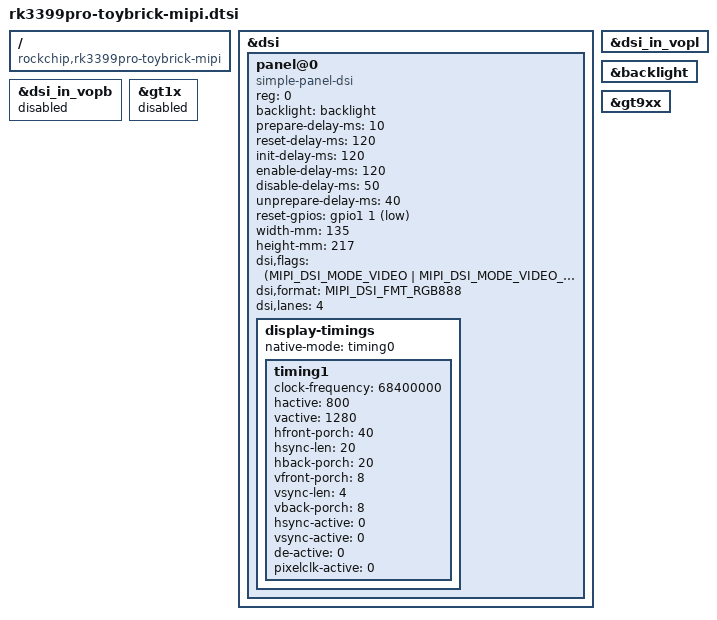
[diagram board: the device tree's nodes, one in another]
/*
 * Copyright (c) 2019 Fuzhou Rockchip Electronics Co., Ltd
 *
 * This file is dual-licensed: you can use it either under the terms
 * of the GPL or the X11 license, at your option. Note that this dual
 * licensing only applies to this file, and not this project as a
 * whole.
 *
 *  a) This file is free software; you can redistribute it and/or
 *     modify it under the terms of the GNU General Public License as
 *     published by the Free Software Foundation; either version 2 of the
 *     License, or (at your option) any later version.
 *
 *     This file is distributed in the hope that it will be useful,
 *     but WITHOUT ANY WARRANTY; without even the implied warranty of
 *     MERCHANTABILITY or FITNESS FOR A PARTICULAR PURPOSE.  See the
 *     GNU General Public License for more details.
 *
 * Or, alternatively,
 *
 *  b) Permission is hereby granted, free of charge, to any person
 *     obtaining a copy of this software and associated documentation
 *     files (the "Software"), to deal in the Software without
 *     restriction, including without limitation the rights to use,
 *     copy, modify, merge, publish, distribute, sublicense, and/or
 *     sell copies of the Software, and to permit persons to whom the
 *     Software is furnished to do so, subject to the following
 *     conditions:
 *
 *     The above copyright notice and this permission notice shall be
 *     included in all copies or substantial portions of the Software.
 *
 *     THE SOFTWARE IS PROVIDED "AS IS", WITHOUT WARRANTY OF ANY KIND,
 *     EXPRESS OR IMPLIED, INCLUDING BUT NOT LIMITED TO THE WARRANTIES
 *     OF MERCHANTABILITY, FITNESS FOR A PARTICULAR PURPOSE AND
 *     NONINFRINGEMENT. IN NO EVENT SHALL THE AUTHORS OR COPYRIGHT
 *     HOLDERS BE LIABLE FOR ANY CLAIM, DAMAGES OR OTHER LIABILITY,
 *     WHETHER IN AN ACTION OF CONTRACT, TORT OR OTHERWISE, ARISING
 *     FROM, OUT OF OR IN CONNECTION WITH THE SOFTWARE OR THE USE OR
 *     OTHER DEALINGS IN THE SOFTWARE.
 */

/ {
	compatible = "rockchip,rk3399pro-toybrick-mipi", "rockchip,rk3399pro";
};

&dsi {
	status = "okay";
	panel@0 {
		compatible = "simple-panel-dsi";
		status = "okay";
		reg = <0>;
		/*power-supply = <&vcc3v3_lcd>;*/
		backlight = <&backlight>;
		prepare-delay-ms = <10>;
		reset-delay-ms = <120>;
		init-delay-ms = <120>;
		enable-delay-ms = <120>;
		disable-delay-ms = <50>;
		unprepare-delay-ms = <40>;
		// enable-gpios = <&gpio4 RK_PD5 GPIO_ACTIVE_HIGH>;
		reset-gpios = <&gpio1 1 GPIO_ACTIVE_LOW>; // gpio 33
		width-mm = <135>;
		height-mm = <217>;

		dsi,flags = <(MIPI_DSI_MODE_VIDEO | MIPI_DSI_MODE_VIDEO_BURST)>;
		dsi,format = <MIPI_DSI_FMT_RGB888>;
		dsi,lanes = <4>;

		display-timings {
			native-mode = <&timing0>;

			timing1: timing1 {
				clock-frequency = <68400000>;
				hactive = <800>;
				vactive = <1280>;
				hfront-porch = <40>;
				hsync-len = <20>;
				hback-porch = <20>;
				vfront-porch = <8>;
				vsync-len = <4>;
				vback-porch = <8>;
				hsync-active = <0>;
				vsync-active = <0>;
				de-active = <0>;
				pixelclk-active = <0>;
			};
		};
	};
};

&dsi_in_vopl {
	status = "okay";
};

&dsi_in_vopb {
	status = "disabled";
};

&backlight {
        status = "okay";
};

&gt1x {
        status = "disabled";
};

&gt9xx {
        status = "okay";
};
